# STM32L053 register map
File version: 1.0
CPU: CM0+ r0p0, little endian, MPU, no FPU, 4 interrupt priority bits
Registers are 32-bit, read-write, reset 0x0 unless marked. A register's access mark holds for its fields unless they carry their own. Offsets are from the block's base; [hi:lo] are bit positions; {n}, {i} and the like mark numbered series.

## USB_SRAM — Universal serial bus full-speed device interface
Base 0x40006000
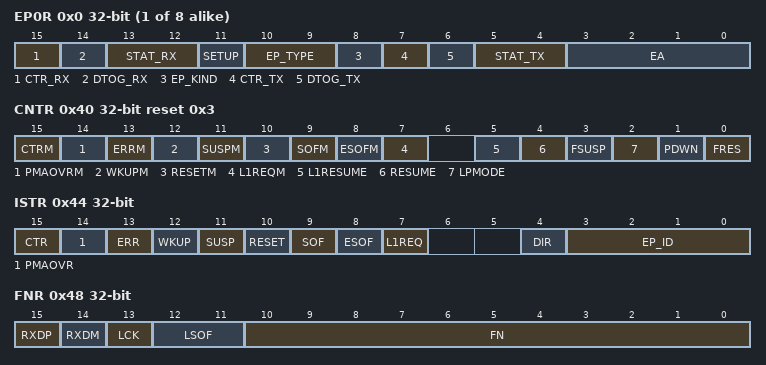
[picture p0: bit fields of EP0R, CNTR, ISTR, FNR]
{0x0+4i} EP{i}R (i=0..7) — endpoint {i} register
  [15] CTR_RX — Correct transfer for reception
  [14] DTOG_RX — Data Toggle, for reception transfers
  [13:12] STAT_RX — Status bits, for reception transfers
  [11] SETUP — Setup transaction completed
  [10:9] EP_TYPE — Endpoint type
  [8] EP_KIND — Endpoint kind
  [7] CTR_TX — Correct Transfer for transmission
  [6] DTOG_TX — Data Toggle, for transmission transfers
  [5:4] STAT_TX — Status bits, for transmission transfers
  [3:0] EA — Endpoint address
0x40 CNTR reset 0x3 — control register
  [15] CTRM — Correct transfer interrupt mask
  [14] PMAOVRM — Packet memory area over / underrun interrupt mask
  [13] ERRM — Error interrupt mask
  [12] WKUPM — Wakeup interrupt mask
  [11] SUSPM — Suspend mode interrupt mask
  [10] RESETM — USB reset interrupt mask
  [9] SOFM — Start of frame interrupt mask
  [8] ESOFM — Expected start of frame interrupt mask
  [7] L1REQM — LPM L1 state request interrupt mask
  [5] L1RESUME — LPM L1 Resume request
  [4] RESUME — Resume request
  [3] FSUSP — Force suspend
  [2] LPMODE — Low-power mode
  [1] PDWN — Power down
  [0] FRES — Force USB Reset
0x44 ISTR access per field — interrupt status register
  [15] CTR ro — Correct transfer
  [14] PMAOVR rw — Packet memory area over / underrun
  [13] ERR rw — Error
  [12] WKUP rw — Wakeup
  [11] SUSP rw — Suspend mode request
  [10] RESET rw — reset request
  [9] SOF rw — start of frame
  [8] ESOF rw — Expected start frame
  [7] L1REQ rw — LPM L1 state request
  [4] DIR ro — Direction of transaction
  [3:0] EP_ID ro — Endpoint Identifier
0x48 FNR ro — frame number register
  [15] RXDP — Receive data + line status
  [14] RXDM — Receive data - line status
  [13] LCK — Locked
  [12:11] LSOF — Lost SOF
  [10:0] FN — Frame number
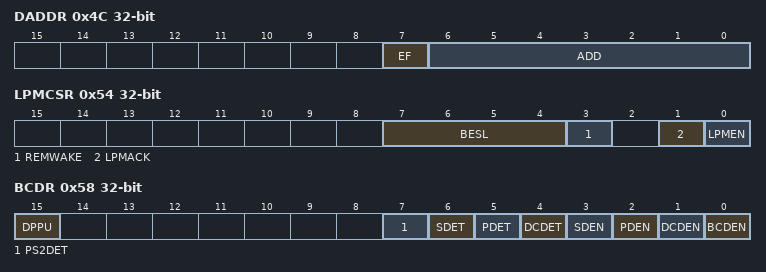
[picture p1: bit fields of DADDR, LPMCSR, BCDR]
0x4C DADDR — device address
  [7] EF — Enable function
  [6:0] ADD — Device address
0x50 BTABLE — Buffer table address
  [15:3] BTABLE — Buffer table
0x54 LPMCSR access per field — LPM control and status register
  [7:4] BESL ro — BESL value
  [3] REMWAKE ro — bRemoteWake value
  [1] LPMACK rw — LPM Token acknowledge enable
  [0] LPMEN rw — LPM support enable
0x58 BCDR access per field — Battery charging detector
  [15] DPPU rw — DP pull-up control
  [7] PS2DET ro — DM pull-up detection status
  [6] SDET ro — Secondary detection
  [5] PDET ro — Primary detection
  [4] DCDET ro — Data contact detection
  [3] SDEN rw — Secondary detection
  [2] PDEN rw — Primary detection
  [1] DCDEN rw — Data contact detection
  [0] BCDEN rw — Battery charging detector

## LCD — Liquid crystal display controller
Base 0x40002400
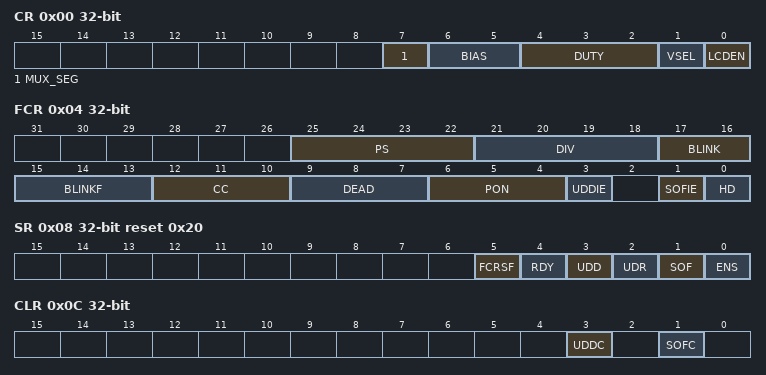
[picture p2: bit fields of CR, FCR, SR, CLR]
0x00 CR — control register
  [7] MUX_SEG — Mux segment enable
  [6:5] BIAS — Bias selector
  [4:2] DUTY — Duty selection
  [1] VSEL — Voltage source selection
  [0] LCDEN — LCD controller enable
0x04 FCR — frame control register
  [25:22] PS — PS 16-bit prescaler
  [21:18] DIV — DIV clock divider
  [17:16] BLINK — Blink mode selection
  [15:13] BLINKF — Blink frequency selection
  [12:10] CC — Contrast control
  [9:7] DEAD — Dead time duration
  [6:4] PON — Pulse ON duration
  [3] UDDIE — Update display done interrupt enable
  [1] SOFIE — Start of frame interrupt enable
  [0] HD — High drive enable
0x08 SR access per field reset 0x20 — status register
  [5] FCRSF ro — LCD Frame Control Register Synchronization flag
  [4] RDY ro — Ready flag
  [3] UDD ro — Update Display Done
  [2] UDR wo — Update display request
  [1] SOF ro — Start of frame flag
  [0] ENS ro
0x0C CLR wo — clear register
  [3] UDDC — Update display done clear
  [1] SOFC — Start of frame flag clear
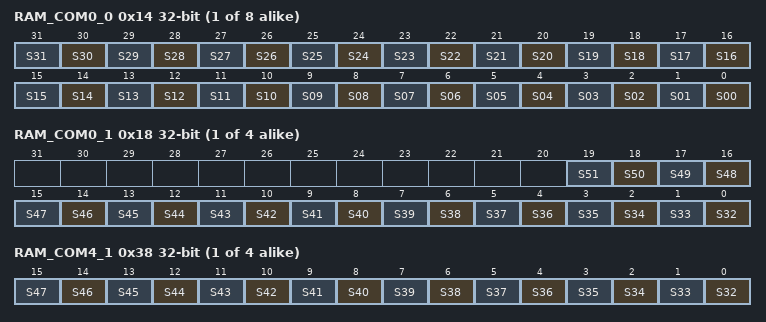
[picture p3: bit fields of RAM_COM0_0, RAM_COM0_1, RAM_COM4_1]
{0x14+8i} RAM_COM{i}_0 (i=0..7) — display memory
  [n] S{n:02} (n=0..31)
{0x18+8i} RAM_COM{i}_1 (i=0..3) — display memory
  [n-32] S{n} (n=32..51)
{0x18+8i} RAM_COM{i}_1 (i=4..7) — display memory
  [n-32] S{n} (n=32..47)

## MPU — Memory protection unit
Base 0xE000ED90
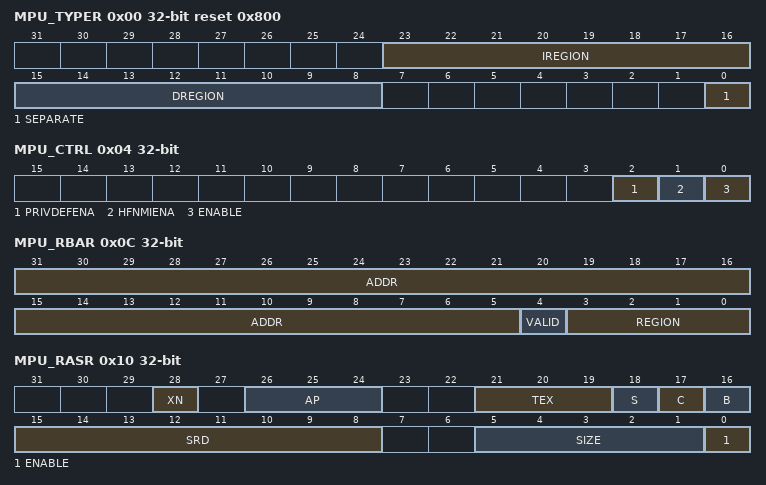
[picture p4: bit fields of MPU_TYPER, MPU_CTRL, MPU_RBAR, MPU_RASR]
0x00 MPU_TYPER ro reset 0x800 — MPU type register
  [23:16] IREGION — Number of MPU instruction regions
  [15:8] DREGION — Number of MPU data regions
  [0] SEPARATE — Separate flag
0x04 MPU_CTRL — MPU control register
  [2] PRIVDEFENA — Enable priviliged software access to default memory map
  [1] HFNMIENA — Enables the operation of MPU during hard fault
  [0] ENABLE — Enables the MPU
0x08 MPU_RNR — MPU region number register
  [7:0] REGION — MPU region
0x0C MPU_RBAR — MPU region base address register
  [31:5] ADDR — Region base address field
  [4] VALID — MPU region number valid
  [3:0] REGION — MPU region field
0x10 MPU_RASR — MPU region attribute and size register
  [28] XN — Instruction access disable bit
  [26:24] AP — Access permission
  [21:19] TEX — memory attribute
  [18] S — Shareable memory attribute
  [17] C — memory attribute
  [16] B — memory attribute
  [15:8] SRD — Subregion disable bits
  [5:1] SIZE — Size of the MPU protection region
  [0] ENABLE — Region enable bit.

## STK — SysTick timer
Base 0xE000E010
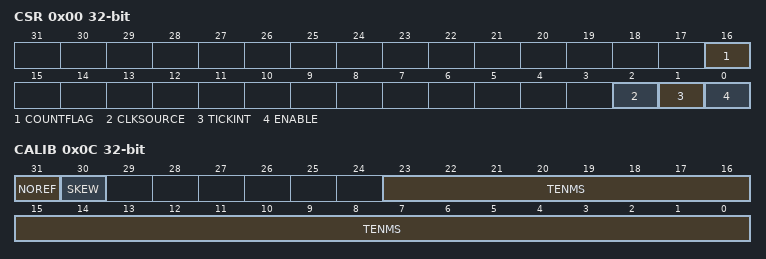
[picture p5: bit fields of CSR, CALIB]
0x00 CSR — SysTick control and status register
  [16] COUNTFLAG
  [2] CLKSOURCE — Clock source selection
  [1] TICKINT — SysTick exception request enable
  [0] ENABLE — Counter enable
0x04 RVR — SysTick reload value register
  [23:0] RELOAD — RELOAD value
0x08 CVR — SysTick current value register
  [23:0] CURRENT — Current counter value
0x0C CALIB — SysTick calibration value register
  [31] NOREF — NOREF flag. Reads as zero
  [30] SKEW — SKEW flag: Indicates whether the TENMS value is exact
  [23:0] TENMS — Calibration value

## SCB — System control block
Base 0xE000ED00
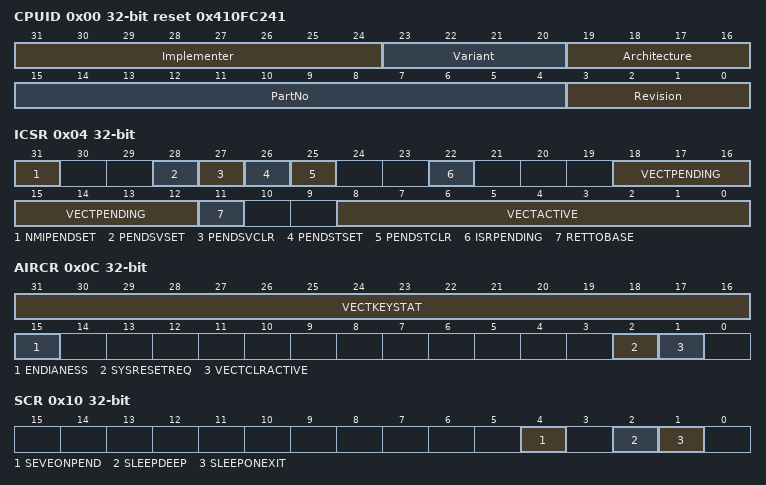
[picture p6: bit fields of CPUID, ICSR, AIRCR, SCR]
0x00 CPUID ro reset 0x410FC241 — CPUID base register
  [31:24] Implementer — Implementer code
  [23:20] Variant — Variant number
  [19:16] Architecture — Reads as 0xF
  [15:4] PartNo — Part number of the processor
  [3:0] Revision — Revision number
0x04 ICSR — Interrupt control and state register
  [31] NMIPENDSET — NMI set-pending bit.
  [28] PENDSVSET — PendSV set-pending bit
  [27] PENDSVCLR — PendSV clear-pending bit
  [26] PENDSTSET — SysTick exception set-pending bit
  [25] PENDSTCLR — SysTick exception clear-pending bit
  [22] ISRPENDING — Interrupt pending flag
  [18:12] VECTPENDING — Pending vector
  [11] RETTOBASE — Return to base level
  [8:0] VECTACTIVE — Active vector
0x08 VTOR — Vector table offset register
  [31:7] TBLOFF — Vector table base offset field
0x0C AIRCR — Application interrupt and reset control register
  [31:16] VECTKEYSTAT — Register key
  [15] ENDIANESS
  [2] SYSRESETREQ
  [1] VECTCLRACTIVE
0x10 SCR — System control register
  [4] SEVEONPEND — Send Event on Pending bit
  [2] SLEEPDEEP
  [1] SLEEPONEXIT
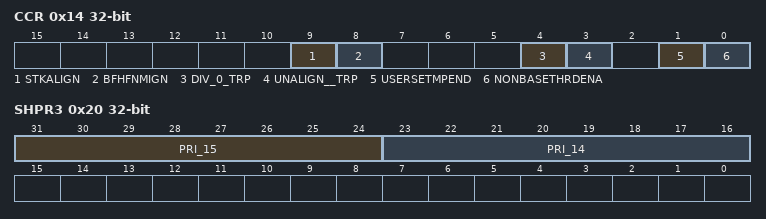
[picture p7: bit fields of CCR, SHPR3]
0x14 CCR — Configuration and control register
  [9] STKALIGN
  [8] BFHFNMIGN
  [4] DIV_0_TRP
  [3] UNALIGN__TRP
  [1] USERSETMPEND
  [0] NONBASETHRDENA — Configures how the processor enters Thread mode
0x1C SHPR2 — System handler priority registers
  [31:24] PRI_11 — Priority of system handler 11
0x20 SHPR3 — System handler priority registers
  [31:24] PRI_15 — Priority of system handler 15
  [23:16] PRI_14 — Priority of system handler 14
